# SC32F10T_10G register map
File version: 1.0
CPU: CM0+ r0p1, little endian, MPU, no FPU, 4 interrupt priority bits
Registers are 32-bit, read-write, reset 0x0 unless marked. A register's access mark holds for its fields unless they carry their own. Offsets are from the block's base; [hi:lo] are bit positions; 'fields as' and 'values as' point back to an identical list.

## UART2
Base 0x40021020
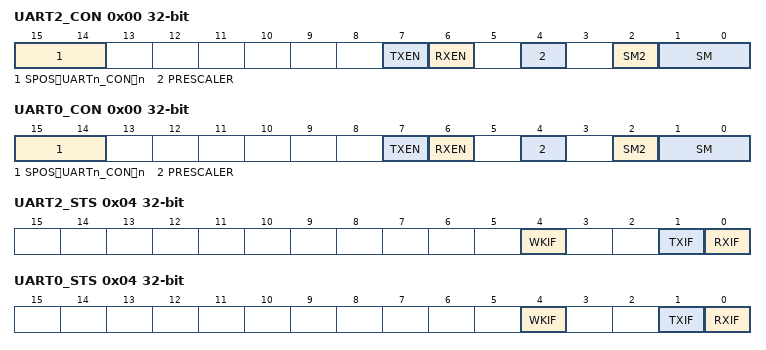
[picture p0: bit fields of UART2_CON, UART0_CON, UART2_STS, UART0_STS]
0x00 UART2_CON — UART控制寄存器
  [15:14] SPOS（UARTn_CON，n — 此bit位，仅在UARTn_CON，n=2的情况下有效：UART2信号口映射控制位@UART2_CON信号SPOS值RX2TX2SPOS[1:0]=00PB0PA15SPOS[1:0]=01PA11PA10
  [7] TXEN — UART发送允许控制位0：不允许发送数据，TXD信号不再影响所在管脚的状态。此时若用户程序限制发送功能，仅用到了接收，那么与TX脚复用的其它功能将不受影响1：允许发送数据，TXD所在管脚切换为TXD信号口模式
  [6] RXEN — UART接收允许控制位0：不允许接收数据1：允许接收数据
  [4] PRESCALER — 波特率倍率设置位该位在UART的不同模式下有不同定义：当SM0~1 = 01（UART模式1）或SM0~1 = 11（UART模式3）：0: 串行端口在系统时钟的1分频下运行1: 串行端口在系统时钟的16分频下运行当SM0~1 = 00（UART模式0）波特率倍率设置位：0：串行端口在系统时钟的12分频下运行1：串行端口在系统时钟的4分频下运行
  [2] SM2 — RB8置位中断允许位该位仅在模式3有效0：每收到一个完整的数据帧就置位RI产生中断请求；1：收到一个完整的数据帧时，只有当RB8=1时才会置位RI产生中断请求
  [1:0] SM — UART通信模式控制位00：模式0，8位半双工同步通信模式，在RX引脚上收发串行数据。TX 引脚用作发送移位时钟。每帧收发8位，低位先接收或发送。在该模式下使能RXEN位，UART将发出一个完整一帧的时钟，并且将RXIF置1；01：模式1，10位全双工异步通信，由1个起始位，8个数据位和1个停止位组成，通信波特率可变；10：保留11：模式3，11位全双工异步通信，由1个起始位，8个数据位，一个可编
0x00 UART0_CON — UART控制寄存器
  fields as UART2_CON
0x04 UART2_STS — UART标志位寄存器
  [4] WKIF — UART唤醒标志位UART从STOP模式唤醒后，该位由硬件置1，如果此时WKIE = 1，将产生中断。该位由软件写1清0。
  [1] TXIF — 发送中断标志位数据发送完成该位由硬件置1，如果此时TXIE = 1，将产生中断。该位由软件写1清0。注意：在DMA模式下，DMA写入发送缓存后，该位由DMA模块清0，此时用户无需通过软件清0。
  [0] RXIF — 接收中断标志位数据接收完成该位由硬件置1，如果此时RXIE = 1，将产生中断。该位由软件写1清0。注意：在DMA模式下，DMA读取接收缓存后，该位由DMA模块清0，此时用户无需通过软件清0。
0x04 UART0_STS — UART标志位寄存器
  fields as UART2_STS
0x08 UART2_BAUD — UART波特率寄存器
  [15:0] BAUD — UART波特率配置位写入BAUD[15:0]后，UART的波特率将按照以下公式配置：BaudRate=fUART / BAUD[15:0]其中fUART为UART时钟源经预分频之后的最终频率，见PRESCALER位说明。
0x08 UART0_BAUD — UART波特率寄存器
  fields as UART2_BAUD
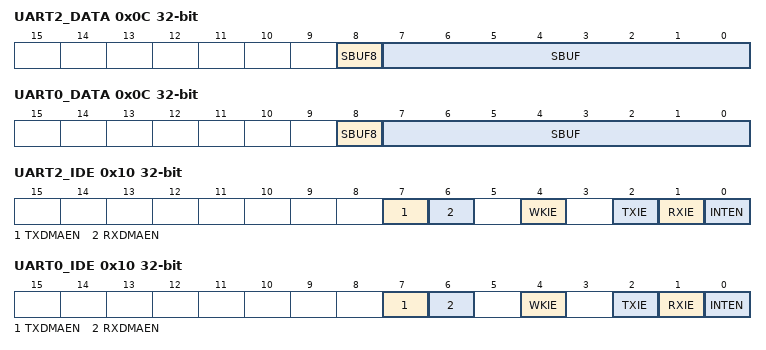
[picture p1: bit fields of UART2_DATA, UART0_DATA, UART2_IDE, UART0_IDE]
0x0C UART2_DATA — UART数据寄存器
  [8] SBUF8 — UART的发送/接收数据的第9位该位仅在模式3有效。
  [7:0] SBUF — UART数据缓存读操作：将返回接收锁存器中的内容写操作：SBUF的数据将送至发送移位寄存器，并启动发送流程
0x0C UART0_DATA — UART数据寄存器
  fields as UART2_DATA
0x10 UART2_IDE — 通信口DMA控制寄存器
  [7] TXDMAEN — DMA发送通道使能位0：禁用DMA发送功能1：使能DMA发送功能该位使能后，TXIF置起可触发DMA通道发送请求注意：UART0和UART1可产生DMA请求UART2和UART3不能产生DMA请求
  [6] RXDMAEN — DMA接收通道使能位0：禁用DMA接收功能1：使能DMA接收功能该位使能后，RXIF置起可触发DMA通道接收请求注意：UART0和UART1可产生DMA请求UART2和UART3不能产生DMA请求
  [4] WKIE — UART唤醒中断使能位0：WKIF置起时，不允许产生中断1：WKIF置起时，产生中断
  [2] TXIE — UART发送中断使能位0：TXIF置起时，不允许产生中断1：TXIF置起时，产生中断
  [1] RXIE — UART接收中断使能位0：RXIF置起时，不允许产生中断1：RXIF置起时，产生中断
  [0] INTEN — 中断请求 CPU的使能控制位0：禁止中断请求1：使能中断请求
0x10 UART0_IDE — 通信口DMA控制寄存器
  fields as UART2_IDE

## SPI0
Base 0x40020040
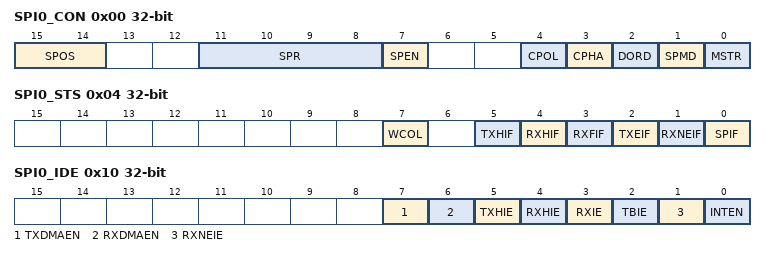
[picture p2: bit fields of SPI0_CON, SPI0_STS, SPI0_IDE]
0x00 SPI0_CON — SPI控制寄存器
  [15:14] SPOS — SPI信号口映射控制位信号SPOS值MISO0MOSI0SCK0SPOS[1:0]=00PA15PB0PB1SPOS[1:0]=01PA3PA2PA1SPOS[1:0]=10PA9PA8PA7
  [11:8] SPR — SPI时钟预分频控制位0000：fPCLK00001：fPCLK0 /20010：fPCLK0 /40011：fPCLK0 /80100：fPCLK0 /160101：fPCLK0 /320110：fPCLK0 /640111：fPCLK0 /1281000：fPCLK0 /2561001：fPCLK0 /5121010：fPCLK0 /1024其它：fPCLK0 /1024
  [7] SPEN — SPI使能控制位0：关闭SPI01：打开SPI0
  [4] CPOL — SPI时钟极性控制位0：SCK在空闲状态下为低电平1：SCK在空闲状态下为高电平
  [3] CPHA — SPI时钟相位控制位0：SCK周期的第一沿采集数据1：SCK周期的第二沿采集数据
  [2] DORD — SPI传送方向选择位0：MSB优先发送1：LSB优先发送
  [1] SPMD — SPI传输模式选择位0：8位模式1：16位模式
  [0] MSTR — SPI主从机模式选择位0：SPI0为从设备1：SPI0为主设备
0x04 SPI0_STS access per field — SPI标志位寄存器
  [7] WCOL rw — 写入冲突标志位该位由硬件置1，通过软件写1清0，用于指示是否发生写入冲突：0：未检测到写入冲突1：检测到一个写入冲突
  [5] TXHIF ro — 发送FIFO内有效数据不满一半状态位/中断状态位该位只读，由硬件置起或清零，用于指示当前发送FIFO的状态：0：发送FIFO中的有效数据个数大于FIFO一半1：发送FIFO中的有效数据个数少于或等于FIFO一半，如果此时TXHIE = 1，将产生中断
  [4] RXHIF ro — 接收FIFO内有效数据超过一半状态位/中断状态位该位只读，由硬件置起或清零，用于指示当前接收FIFO的状态：0：接收FIFO的有效数据个数少于或等于FIFO一半1：接收FIFO的有效数据个数大于FIFO一半，如果此时RXHIE = 1，将产生中断
  [3] RXFIF ro — 接收FIFO已满状态位该位只读，由硬件置起或清零，用于指示当前接收FIFO是否已满：0：接收FIFO未满1：接收FIFO已满
  [2] TXEIF rw — 发送FIFO为空标志位用于指示当前发送FIFO是否为空：0：发送FIFO非空1：发送FIFO为空该位由硬件置1，通过软件写1清0。注意：在DMA模式下，DMA写入发送缓存后，该位由DMA模块清0，此时用户无需通过软件清0。
  [1] RXNEIF rw — 接收FIFO非空状态位用于指示当前接收FIFO是否为空： 0：接收FIFO为空1：接收FIFO非空该位由硬件置1，通过软件写1清0。注意：在DMA模式下，DMA读取接收缓存后，该位由DMA模块清零，此时用户无需通过软件清0。
  [0] SPIF rw — SPI数据传送标志位该位由硬件置1，通过软件写1清0，用于指示当前SPI数据传输是否完成：0：数据传输未完成/进行中1：数据传输已完成
0x0C SPI0_DATA — SPI数据寄存器
  [15:0] SPD — SPI数据缓存读操作：从SPI0接收FIFO读取接收到的数据写操作：向SPI0发送FIFO写入待发送的数据
0x10 SPI0_IDE — 通信口DMA控制寄存器
  [7] TXDMAEN — DMA发送通道使能位0：禁用DMA发送功能1：使能DMA发送功能该位使能后，TXEIF置起可触发DMA通道发送请求
  [6] RXDMAEN — DMA接收通道使能位0：禁用DMA接收功能1：使能DMA接收功能该位使能后，RXNEIF置起可触发DMA通道接收请求
  [5] TXHIE — 发送FIFO内有效数据不满一半中断使能位0：TXHIF置起时，不允许产生中断1：TXHIF置起时，产生中断
  [4] RXHIE — 接收FIFO内有效数据超过一半中断使能位0：RXHIF置起时，不允许产生中断1：RXHIF置起时，产生中断
  [3] RXIE — 接收FIFO已满中断使能位0：RXFIF置起时，不允许产生中断1：RXFIF置起时，产生中断
  [2] TBIE — 发送FIFO为空时的中断使能位0：TXEIF置起时，不允许产生中断1：TXEIF置起时，产生中断
  [1] RXNEIE — 接收FIFO非空中断使能位0：RXNEIF置起，不允许产生中断1：RXNEIF置起，产生中断
  [0] INTEN — 中断请求 CPU的使能控制位0：禁止中断请求1：使能中断请求
